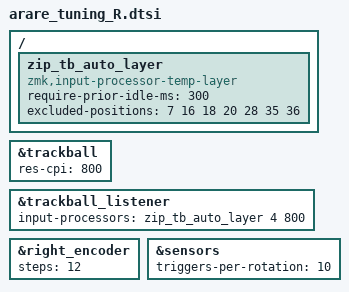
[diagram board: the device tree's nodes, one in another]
/* arare チューニング（右手）: トラックボール＋右エンコーダ（受け口）
 *
 * このファイルは arare Studio の「トラックボール設定」パネルが生成するテキストで
 * まるごと差し替える運用（手で編集してもよい）。
 * 既定値 = CPI 800・向き補正なし・スクロール/スナイプ無効・オートマウス有効
 * （ボールを動かすと 800ms だけ L4 へ。L4 の I=中・J=左・L=右クリック。moNa2 のマウスレイヤーと同じ並び）。
 *
 * 実機での微調整は DYA Studio（cormoranフォーク）でも可能だが、
 * ここに書いた値がファームウェア本体の既定値になる。
 */

#include <input/processors.dtsi>
#include <dt-bindings/zmk/input_transform.h>

&trackball {
    res-cpi = <800>;
};

/ {
    /* オートマウス（一時レイヤー）用プロセッサ。
     * 打鍵から 300ms 以内はボールが動いても切り替えない（打鍵中の誤発動防止）。
     * excluded-positions = マウス用レイヤーで割り当てたキー（I=7・J=18・L=20）、元からクリックのキー
     * （ホイール押込=16・右クリック=28）、押しても文字が出ない修飾キー（⌥/⌃=35・⌘=36。⌘クリックのため）。
     * これ以外のキーを押すとすぐ元に戻り、これらは押してもレイヤーが続く（続けてクリックできる）。
     * A（長押しで⌃）と 英数（長押しで⇧）はタップで文字・切替が出るので入れない（打ちはじめで抜けるように） */
    zip_tb_auto_layer: zip_tb_auto_layer {
        compatible = "zmk,input-processor-temp-layer";
        #input-processor-cells = <2>;
        require-prior-idle-ms = <300>;
        excluded-positions = <7 16 18 20 28 35 36>;
    };
};

/* オートマウス: ボールを動かしている間と、止めてから 800ms は L4（マウス用レイヤー） */
&trackball_listener {
    input-processors = <&zip_tb_auto_layer 4 800>;
};

/* ---- arare Studio が生成するブロックの例 ----
&trackball_listener {
    input-processors
        = <&zip_xy_transform (INPUT_TRANSFORM_XY_SWAP | INPUT_TRANSFORM_X_INVERT)>
        , <&zip_xy_scaler 3 2>
        , <&zip_tb_auto_layer 2 800>;

    scroller {
        layers = <1>;
        input-processors
            = <&zip_xy_to_scroll_mapper>
            , <&zip_scroll_scaler 1 8>
            , <&zip_scroll_transform INPUT_TRANSFORM_Y_INVERT>;
    };

    sniper {
        layers = <2>;
        input-processors = <&zip_xy_scaler 1 3>;
    };
};
------------------------------------------------ */

/* 右エンコーダ（CKW12・水平）の分解能と感度 */
&right_encoder {
    steps = <12>;
};

&sensors {
    triggers-per-rotation = <10>;
};
